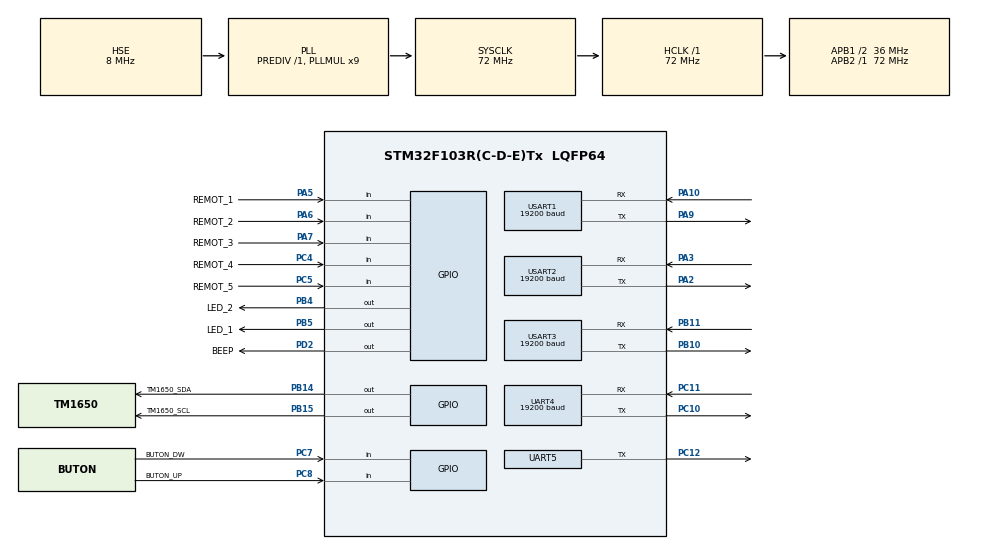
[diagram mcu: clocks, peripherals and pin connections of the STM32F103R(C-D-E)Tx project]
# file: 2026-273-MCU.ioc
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Dma.Request0=UART4_RX
Dma.Request1=USART1_RX
Dma.Request2=USART2_RX
Dma.Request3=USART3_RX
Dma.UART4_RX.0.Direction=DMA_PERIPH_TO_MEMORY
Dma.UART4_RX.0.Instance=DMA2_Channel3
Dma.UART4_RX.0.MemDataAlignment=DMA_MDATAALIGN_BYTE
Dma.UART4_RX.0.MemInc=DMA_MINC_ENABLE
Dma.UART4_RX.0.Mode=DMA_NORMAL
Dma.UART4_RX.0.PeriphDataAlignment=DMA_PDATAALIGN_BYTE
Dma.UART4_RX.0.PeriphInc=DMA_PINC_DISABLE
Dma.UART4_RX.0.Priority=DMA_PRIORITY_LOW
Dma.USART1_RX.1.Direction=DMA_PERIPH_TO_MEMORY
Dma.USART1_RX.1.Instance=DMA1_Channel5
Dma.USART1_RX.1.MemDataAlignment=DMA_MDATAALIGN_BYTE
Dma.USART1_RX.1.MemInc=DMA_MINC_ENABLE
Dma.USART1_RX.1.Mode=DMA_NORMAL
Dma.USART1_RX.1.PeriphDataAlignment=DMA_PDATAALIGN_BYTE
Dma.USART1_RX.1.PeriphInc=DMA_PINC_DISABLE
Dma.USART1_RX.1.Priority=DMA_PRIORITY_LOW
Dma.USART2_RX.2.Direction=DMA_PERIPH_TO_MEMORY
Dma.USART2_RX.2.Instance=DMA1_Channel6
Dma.USART2_RX.2.MemDataAlignment=DMA_MDATAALIGN_BYTE
Dma.USART2_RX.2.MemInc=DMA_MINC_ENABLE
Dma.USART2_RX.2.Mode=DMA_NORMAL
Dma.USART2_RX.2.PeriphDataAlignment=DMA_PDATAALIGN_BYTE
Dma.USART2_RX.2.PeriphInc=DMA_PINC_DISABLE
Dma.USART2_RX.2.Priority=DMA_PRIORITY_LOW
Dma.USART3_RX.3.Direction=DMA_PERIPH_TO_MEMORY
Dma.USART3_RX.3.Instance=DMA1_Channel3
Dma.USART3_RX.3.MemDataAlignment=DMA_MDATAALIGN_BYTE
Dma.USART3_RX.3.MemInc=DMA_MINC_ENABLE
Dma.USART3_RX.3.Mode=DMA_NORMAL
Dma.USART3_RX.3.PeriphDataAlignment=DMA_PDATAALIGN_BYTE
Dma.USART3_RX.3.PeriphInc=DMA_PINC_DISABLE
Dma.USART3_RX.3.Priority=DMA_PRIORITY_LOW
FREERTOS.Tasks01=defaultTask,24,64,StartDefaultTask,Default,NULL,Dynamic,NULL,NULL
FREERTOS.configMINIMAL_STACK_SIZE=64
FREERTOS.configTOTAL_HEAP_SIZE=10240
Mcu.Family=STM32F1
Mcu.Name=STM32F103R(C-D-E)Tx
Mcu.Package=LQFP64
NVIC.DMA1_Channel3_IRQn=true\:5\:0\:false\:false\:true\:true\:false\:true\:true
NVIC.DMA1_Channel5_IRQn=true\:5\:0\:false\:false\:true\:true\:false\:true\:true
NVIC.DMA1_Channel6_IRQn=true\:5\:0\:false\:false\:true\:true\:false\:true\:true
NVIC.DMA2_Channel3_IRQn=true\:5\:0\:false\:false\:true\:true\:false\:true\:true
NVIC.PVD_IRQn=true\:5\:0\:false\:false\:true\:true\:true\:true\:true
NVIC.PriorityGroup=NVIC_PRIORITYGROUP_4
NVIC.TIM7_IRQn=true\:15\:0\:false\:false\:true\:false\:false\:true\:true
NVIC.TimeBase=TIM7_IRQn
NVIC.TimeBaseIP=TIM7
NVIC.UART4_IRQn=true\:5\:0\:false\:false\:true\:true\:true\:true\:true
NVIC.USART1_IRQn=true\:5\:0\:false\:false\:true\:true\:true\:true\:true
NVIC.USART2_IRQn=true\:5\:0\:false\:false\:true\:true\:true\:true\:true
NVIC.USART3_IRQn=true\:5\:0\:false\:false\:true\:true\:true\:true\:true
PA10.Mode=Asynchronous
PA10.Signal=USART1_RX
PA13.Mode=Serial_Wire
PA13.Signal=SYS_JTMS-SWDIO
PA14.Mode=Serial_Wire
PA14.Signal=SYS_JTCK-SWCLK
PA2.Mode=Asynchronous
PA2.Signal=USART2_TX
PA3.Mode=Asynchronous
PA3.Signal=USART2_RX
PA5.GPIO_Label=REMOT_1
PA5.Signal=GPIO_Input
PA6.GPIO_Label=REMOT_2
PA6.Signal=GPIO_Input
PA7.GPIO_Label=REMOT_3
PA7.Signal=GPIO_Input
PA9.Mode=Asynchronous
PA9.Signal=USART1_TX
PB10.Mode=Asynchronous
PB10.Signal=USART3_TX
PB11.Mode=Asynchronous
PB11.Signal=USART3_RX
PB14.GPIO_Label=TM1650_SDA
PB14.GPIO_ModeDefaultOutputPP=GPIO_MODE_OUTPUT_OD
PB14.GPIO_PuPd=GPIO_NOPULL
PB14.GPIO_Speed=GPIO_SPEED_FREQ_MEDIUM
PB14.Signal=GPIO_Output
PB15.GPIO_Label=TM1650_SCL
PB15.GPIO_ModeDefaultOutputPP=GPIO_MODE_OUTPUT_OD
PB15.GPIO_PuPd=GPIO_NOPULL
PB15.GPIO_Speed=GPIO_SPEED_FREQ_MEDIUM
PB15.Signal=GPIO_Output
PB4.GPIO_Label=LED_2
PB4.Signal=GPIO_Output
PB5.GPIO_Label=LED_1
PB5.Signal=GPIO_Output
PC10.Mode=Asynchronous
PC10.Signal=UART4_TX
PC11.Mode=Asynchronous
PC11.Signal=UART4_RX
PC12.Mode=Asynchronous
PC12.Signal=UART5_TX
PC4.GPIO_Label=REMOT_4
PC4.Signal=GPIO_Input
PC5.GPIO_Label=REMOT_5
PC5.Signal=GPIO_Input
PC7.GPIO_Label=BUTON_DW
PC7.Signal=GPIO_Input
PC8.GPIO_Label=BUTON_UP
PC8.Signal=GPIO_Input
PD0-OSC_IN.Mode=HSE-External-Oscillator
PD0-OSC_IN.Signal=RCC_OSC_IN
PD1-OSC_OUT.Mode=HSE-External-Oscillator
PD1-OSC_OUT.Signal=RCC_OSC_OUT
PD2.GPIO_Label=BEEP
PD2.Signal=GPIO_Output
ProjectManager.HeapSize=0x200
ProjectManager.StackSize=0x400
ProjectManager.TargetToolchain=MDK-ARM V5.32
RCC.AHBFreq_Value=72000000
RCC.APB1CLKDivider=RCC_HCLK_DIV2
RCC.APB1Freq_Value=36000000
RCC.APB1TimFreq_Value=72000000
RCC.APB2Freq_Value=72000000
RCC.APB2TimFreq_Value=72000000
RCC.HCLKFreq_Value=72000000
RCC.PLLMUL=RCC_PLL_MUL9
RCC.PLLSourceVirtual=RCC_PLLSOURCE_HSE
RCC.SYSCLKFreq_VALUE=72000000
RCC.SYSCLKSource=RCC_SYSCLKSOURCE_PLLCLK
RCC.USBFreq_Value=72000000
UART4.BaudRate=19200
UART4.VirtualMode=Asynchronous
UART5.VirtualMode=Asynchronous
USART1.BaudRate=19200
USART1.VirtualMode=VM_ASYNC
USART2.BaudRate=19200
USART2.VirtualMode=VM_ASYNC
USART3.BaudRate=19200
USART3.VirtualMode=VM_ASYNC
VP_FREERTOS_VS_CMSIS_V2.Mode=CMSIS_V2
VP_SYS_VS_tim7.Mode=TIM7
board=custom

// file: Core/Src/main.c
/* USER CODE BEGIN Header */
/**
  ******************************************************************************
  * @file           : main.c
  * @brief          : Main program body
  ******************************************************************************
  * @attention
  *
  * Copyright (c) 2026 STMicroelectronics.
  * All rights reserved.
  *
  * This software is licensed under terms that can be found in the LICENSE file
  * in the root directory of this software component.
  * If no LICENSE file comes with this software, it is provided AS-IS.
  *
  ******************************************************************************
  */
/* USER CODE END Header */
#include "main.h"
#include "cmsis_os.h"
#include "dma.h"
#include "usart.h"
#include "gpio.h"

void SystemClock_Config(void);
void MX_FREERTOS_Init(void);

int main(void)
{

  /* MCU Configuration--------------------------------------------------------*/

  /* Reset of all peripherals, Initializes the Flash interface and the Systick. */
  HAL_Init();

  /* Configure the system clock */
  SystemClock_Config();

  /* Initialize all configured peripherals */
  MX_GPIO_Init();
  MX_DMA_Init();
  MX_UART4_Init();
  MX_USART1_UART_Init();
  MX_USART2_UART_Init();
  MX_USART3_UART_Init();
  MX_UART5_Init();

  /* Init scheduler */
  osKernelInitialize();  /* Call init function for freertos objects (in cmsis_os2.c) */
  MX_FREERTOS_Init();

  /* Start scheduler */
  osKernelStart();

  /* We should never get here as control is now taken by the scheduler */

  /* Infinite loop */
  while (1)
  {

  }
}

void SystemClock_Config(void)
{
  RCC_OscInitTypeDef RCC_OscInitStruct = {0};
  RCC_ClkInitTypeDef RCC_ClkInitStruct = {0};

  /** Initializes the RCC Oscillators according to the specified parameters
  * in the RCC_OscInitTypeDef structure.
  */
  RCC_OscInitStruct.OscillatorType = RCC_OSCILLATORTYPE_HSE;
  RCC_OscInitStruct.HSEState = RCC_HSE_ON;
  RCC_OscInitStruct.HSEPredivValue = RCC_HSE_PREDIV_DIV1;
  RCC_OscInitStruct.HSIState = RCC_HSI_ON;
  RCC_OscInitStruct.PLL.PLLState = RCC_PLL_ON;
  RCC_OscInitStruct.PLL.PLLSource = RCC_PLLSOURCE_HSE;
  RCC_OscInitStruct.PLL.PLLMUL = RCC_PLL_MUL9;
  if (HAL_RCC_OscConfig(&RCC_OscInitStruct) != HAL_OK)
  {
    Error_Handler();
  }

  /** Initializes the CPU, AHB and APB buses clocks
  */
  RCC_ClkInitStruct.ClockType = RCC_CLOCKTYPE_HCLK|RCC_CLOCKTYPE_SYSCLK
                              |RCC_CLOCKTYPE_PCLK1|RCC_CLOCKTYPE_PCLK2;
  RCC_ClkInitStruct.SYSCLKSource = RCC_SYSCLKSOURCE_PLLCLK;
  RCC_ClkInitStruct.AHBCLKDivider = RCC_SYSCLK_DIV1;
  RCC_ClkInitStruct.APB1CLKDivider = RCC_HCLK_DIV2;
  RCC_ClkInitStruct.APB2CLKDivider = RCC_HCLK_DIV1;

  if (HAL_RCC_ClockConfig(&RCC_ClkInitStruct, FLASH_LATENCY_2) != HAL_OK)
  {
    Error_Handler();
  }
}

void HAL_TIM_PeriodElapsedCallback(TIM_HandleTypeDef *htim)
{
  if (htim->Instance == TIM7)
  {
    HAL_IncTick();
  }
}

void Error_Handler(void)
{
  __disable_irq();
  while (1)
  {
  }
}

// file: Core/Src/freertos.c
/* USER CODE BEGIN Header */
/**
 ******************************************************************************
 * File Name          : freertos.c
 * Description        : Code for freertos applications
 ******************************************************************************
 * @attention
 *
 * Copyright (c) 2026 STMicroelectronics.
 * All rights reserved.
 *
 * This software is licensed under terms that can be found in the LICENSE file
 * in the root directory of this software component.
 * If no LICENSE file comes with this software, it is provided AS-IS.
 *
 ******************************************************************************
 */
/* USER CODE END Header */

#include "FreeRTOS.h"
#include "task.h"
#include "main.h"
#include "cmsis_os.h"

/* USER CODE BEGIN Includes */
#include "app_main.h"
/* USER CODE END Includes */

/* Definitions for defaultTask */
osThreadId_t defaultTaskHandle;
const osThreadAttr_t defaultTask_attributes = {
    .name       = "defaultTask",
    .stack_size = 256 * 4,
    .priority   = (osPriority_t)osPriorityNormal,
};

void StartDefaultTask(void *argument);

void MX_FREERTOS_Init(void); /* (MISRA C 2004 rule 8.1) */

void MX_FREERTOS_Init(void)
{

    /* Create the thread(s) */
    /* creation of defaultTask */
    defaultTaskHandle = osThreadNew(StartDefaultTask, NULL, &defaultTask_attributes);

}

void StartDefaultTask(void *argument)
{
    /* USER CODE BEGIN StartDefaultTask */
    APP_Init();
    osThreadSetPriority(defaultTaskHandle, osPriorityLow);
    vTaskDelete(NULL);
    /* Infinite loop */
    for (;;) {
        osDelay(100);
    }
    /* USER CODE END StartDefaultTask */
}

/* USER CODE BEGIN Application */
void vApplicationStackOverflowHook(TaskHandle_t xTask, signed char *pcTaskName)
{
    (void)xTask;
    Debug_Printf("[FATAL] FreeRTOS Stack Overflow in Task: %s\r\n", (const char *)pcTaskName);
    taskDISABLE_INTERRUPTS();
    for (;;);
}
/* USER CODE END Application */
